AUTOSAR XML (schema 4-0-3)
package /CalibrationComponents
  parameter sw component type HVIR: data-type-mapping=HVIR_CodeDataTypeMappingsSet
    provide port HVIR_Pport: provided-interface=HVIR_if
      provided-com-specs:
        init-value=0.009999999776482582, parameter=KeHVIR_I_FastChgCurrentLoop
        init-value=0.009999999776482582, parameter=KeHVIR_I_MainCurrentLoop
        init-value=400, parameter=KeHVIR_R_FastChgLoopResThreshold
        init-value=400, parameter=KeHVIR_R_MainLoopResThreshold
        init-value=0, parameter=KeHVIR_U_HS_HVILFaultedDflt
        init-value=0, parameter=KeHVIR_U_HS_HVILFaultedDflt1
        init-value=0, parameter=KeHVIR_U_LS_HVILFaultedDflt
        init-value=0, parameter=KeHVIR_U_LS_HVILFaultedDflt1
        init-value=0, parameter=KeHVIR_U_OvrdHS2_HVILVal
        init-value=0, parameter=KeHVIR_U_OvrdHS_HVIL1Val
        init-value=0, parameter=KeHVIR_U_OvrdHS_HVILVal
        init-value=0, parameter=KeHVIR_U_OvrdLS2_HVILVal
        init-value=0, parameter=KeHVIR_U_OvrdLS_HVIL1Val
        init-value=0, parameter=KeHVIR_U_OvrdLS_HVILVal
        init-value=0.10000000149011612, parameter=KeHVIR_t_MainLoopHVILFltOffDbnc
        init-value=1, parameter=KeHVIR_t_MainLoopHVILFltOnDbnc
        init-value=0.009999999776482582, parameter=KeHVIR_t_SampleRate
        init-value=5, parameter=KeHVIR_Cnt_DbncFastChgCommFlt
        init-value=5, parameter=KeHVIR_Cnt_DbncMainCommFlt
        init-value=100, parameter=KeHVIR_Cnt_FastChgLoopHVILFltDbnc
        init-value=CeHVIR_e_HVIL_Closed, parameter=KeHVIR_e_MainHVIL2_StOvrdVal
        init-value=CeHVIR_e_HVIL_Closed, parameter=KeHVIR_e_MainHVIL_StOvrdVal
        init-value=CeHVIR_e_HVIL_ClosedFS, parameter=KeHVIR_e_FastChrgHVIL_StOvrdVal
        init-value=0, parameter=KeHVIR_b_FastChgHVIL_fltOvrd
        init-value=0, parameter=KeHVIR_b_FastChgHVIL_fltOvrdVal
        init-value=0, parameter=KeHVIR_b_FastChrgHVIL_StOvrdCtrl
        init-value=0, parameter=KeHVIR_b_MainHVIL2_StOvrd
        init-value=0, parameter=KeHVIR_b_MainHVIL2_flt_Ctrl
        init-value=0, parameter=KeHVIR_b_MainHVIL_StOvrd
        init-value=0, parameter=KeHVIR_b_MainHVIL_flt_Ctrl
        init-value=0, parameter=KeHVIR_b_OvrdHS2_HVILFltOvrd
        init-value=0, parameter=KeHVIR_b_OvrdHS2_HVILFltVal
        init-value=0, parameter=KeHVIR_b_OvrdHS2_HVILOvrd
        init-value=0, parameter=KeHVIR_b_OvrdHS_HVIL1Ovrd
        init-value=0, parameter=KeHVIR_b_OvrdHS_HVILFlt1Ovrd
        init-value=0, parameter=KeHVIR_b_OvrdHS_HVILFlt1Val
        init-value=0, parameter=KeHVIR_b_OvrdHS_HVILFltOvrd
        init-value=0, parameter=KeHVIR_b_OvrdHS_HVILFltVal
        init-value=0, parameter=KeHVIR_b_OvrdHS_HVILOvrd
        init-value=0, parameter=KeHVIR_b_OvrdLS2_HVILFltOvrd
        init-value=0, parameter=KeHVIR_b_OvrdLS2_HVILFltVal
        init-value=0, parameter=KeHVIR_b_OvrdLS2_HVILOvrd
        init-value=0, parameter=KeHVIR_b_OvrdLS_HVIL1Ovrd
        init-value=0, parameter=KeHVIR_b_OvrdLS_HVILFlt1Ovrd
        init-value=0, parameter=KeHVIR_b_OvrdLS_HVILFlt1Val
        init-value=0, parameter=KeHVIR_b_OvrdLS_HVILFltOvrd
        init-value=0, parameter=KeHVIR_b_OvrdLS_HVILFltVal
        init-value=0, parameter=KeHVIR_b_OvrdLS_HVILOvrd
        init-value=0, parameter=KeHVIR_k_MainHVIL2_flt_Val
        init-value=0, parameter=KeHVIR_k_MainHVIL_flt_Val
package /HVIR_Code_pkg/HVIR_Code_swc
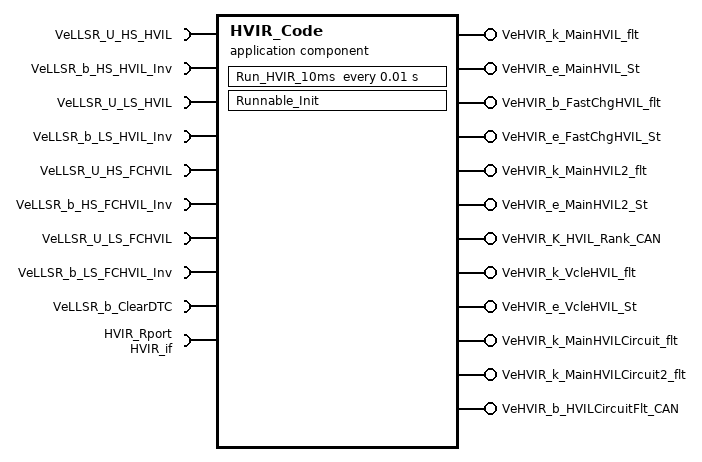
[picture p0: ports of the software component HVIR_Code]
  application sw component type HVIR_Code
    9 x require port:
      VeLLSR_U_HS_HVIL: nonqueued-receiver-com-spec{data-element=VeLLSR_U_HS_HVIL, init-value=0}, required-interface=VeLLSR_U_HS_HVIL
      VeLLSR_b_HS_HVIL_Inv: nonqueued-receiver-com-spec{data-element=VeLLSR_b_HS_HVIL_Inv, init-value=0}, required-interface=VeLLSR_b_HS_HVIL_Inv
      VeLLSR_U_LS_HVIL: nonqueued-receiver-com-spec{data-element=VeLLSR_U_LS_HVIL, init-value=0}, required-interface=VeLLSR_U_LS_HVIL
      VeLLSR_b_LS_HVIL_Inv: nonqueued-receiver-com-spec{data-element=VeLLSR_b_LS_HVIL_Inv, init-value=0}, required-interface=VeLLSR_b_LS_HVIL_Inv
      VeLLSR_U_HS_FCHVIL: nonqueued-receiver-com-spec{data-element=VeLLSR_U_HS_FCHVIL, init-value=0}, required-interface=VeLLSR_U_HS_FCHVIL
      VeLLSR_b_HS_FCHVIL_Inv: nonqueued-receiver-com-spec{data-element=VeLLSR_b_HS_FCHVIL_Inv, init-value=0}, required-interface=VeLLSR_b_HS_FCHVIL_Inv
      VeLLSR_U_LS_FCHVIL: nonqueued-receiver-com-spec{data-element=VeLLSR_U_LS_FCHVIL, init-value=0}, required-interface=VeLLSR_U_LS_FCHVIL
      VeLLSR_b_LS_FCHVIL_Inv: nonqueued-receiver-com-spec{data-element=VeLLSR_b_LS_FCHVIL_Inv, init-value=0}, required-interface=VeLLSR_b_LS_FCHVIL_Inv
      VeLLSR_b_ClearDTC: nonqueued-receiver-com-spec{data-element=VeLLSR_b_ClearDTC, init-value=0}, required-interface=VeLLSR_b_ClearDTC
    12 x provide port:
      VeHVIR_k_MainHVIL_flt: nonqueued-sender-com-spec{data-element=VeHVIR_k_MainHVIL_flt, init-value=0}, provided-interface=VeHVIR_k_MainHVIL_flt
      VeHVIR_e_MainHVIL_St: nonqueued-sender-com-spec{data-element=VeHVIR_e_MainHVIL_St, init-value=CeHVIR_e_HVIL_Closed}, provided-interface=VeHVIR_e_MainHVIL_St
      VeHVIR_b_FastChgHVIL_flt: nonqueued-sender-com-spec{data-element=VeHVIR_b_FastChgHVIL_flt, init-value=0}, provided-interface=VeHVIR_b_FastChgHVIL_flt
      VeHVIR_e_FastChgHVIL_St: nonqueued-sender-com-spec{data-element=VeHVIR_e_FastChgHVIL_St, init-value=CeHVIR_e_HVIL_ClosedFS}, provided-interface=VeHVIR_e_FastChgHVIL_St
      VeHVIR_k_MainHVIL2_flt: nonqueued-sender-com-spec{data-element=VeHVIR_k_MainHVIL2_flt, init-value=0}, provided-interface=VeHVIR_k_MainHVIL2_flt
      VeHVIR_e_MainHVIL2_St: nonqueued-sender-com-spec{data-element=VeHVIR_e_MainHVIL2_St, init-value=CeHVIR_e_HVIL_Closed}, provided-interface=VeHVIR_e_MainHVIL2_St
      VeHVIR_K_HVIL_Rank_CAN: nonqueued-sender-com-spec{data-element=VeHVIR_K_HVIL_Rank_CAN, init-value=0}, provided-interface=VeHVIR_K_HVIL_Rank_CAN
      VeHVIR_k_VcleHVIL_flt: nonqueued-sender-com-spec{data-element=VeHVIR_k_VcleHVIL_flt, init-value=0}, provided-interface=VeHVIR_k_VcleHVIL_flt
      VeHVIR_e_VcleHVIL_St: nonqueued-sender-com-spec{data-element=VeHVIR_e_VcleHVIL_St, init-value=0}, provided-interface=VeHVIR_e_VcleHVIL_St
      VeHVIR_k_MainHVILCircuit_flt: nonqueued-sender-com-spec{data-element=VeHVIR_k_MainHVILCircuit_flt, init-value=0}, provided-interface=VeHVIR_k_MainHVILCircuit_flt
      VeHVIR_k_MainHVILCircuit2_flt: nonqueued-sender-com-spec{data-element=VeHVIR_k_MainHVILCircuit2_flt, init-value=0}, provided-interface=VeHVIR_k_MainHVILCircuit2_flt
      VeHVIR_b_HVILCircuitFlt_CAN: nonqueued-sender-com-spec{data-element=VeHVIR_b_HVILCircuitFlt_CAN, init-value=0}, provided-interface=VeHVIR_b_HVILCircuitFlt_CAN
    require port HVIR_Rport: required-interface=HVIR_if
    behavior HVIR_Code: data-type-mapping=HVIR_CodeDataTypeMappingsSet, handle-termination-and-restart=NO-SUPPORT
      timing event Event_Run_HVIR_10ms: start-on-event=Run_HVIR_10ms, period=0.01
      runnable Runnable_Init: symbol=HVIR_Code_Init
      runnable Run_HVIR_10ms
        data-read-access:
          9 x access:
            IN_VeLLSR_U_HS_FCHVIL_VeLLSR_U_HS_FCHVIL: accessed-variable=VeLLSR_U_HS_FCHVIL.VeLLSR_U_HS_FCHVIL
            IN_VeLLSR_U_HS_HVIL_VeLLSR_U_HS_HVIL: accessed-variable=VeLLSR_U_HS_HVIL.VeLLSR_U_HS_HVIL
            IN_VeLLSR_U_LS_FCHVIL_VeLLSR_U_LS_FCHVIL: accessed-variable=VeLLSR_U_LS_FCHVIL.VeLLSR_U_LS_FCHVIL
            IN_VeLLSR_U_LS_HVIL_VeLLSR_U_LS_HVIL: accessed-variable=VeLLSR_U_LS_HVIL.VeLLSR_U_LS_HVIL
            IN_VeLLSR_b_ClearDTC_VeLLSR_b_ClearDTC: accessed-variable=VeLLSR_b_ClearDTC.VeLLSR_b_ClearDTC
            IN_VeLLSR_b_HS_FCHVIL_Inv_VeLLSR_b_HS_FCHVIL_Inv: accessed-variable=VeLLSR_b_HS_FCHVIL_Inv.VeLLSR_b_HS_FCHVIL_Inv
            IN_VeLLSR_b_HS_HVIL_Inv_VeLLSR_b_HS_HVIL_Inv: accessed-variable=VeLLSR_b_HS_HVIL_Inv.VeLLSR_b_HS_HVIL_Inv
            IN_VeLLSR_b_LS_FCHVIL_Inv_VeLLSR_b_LS_FCHVIL_Inv: accessed-variable=VeLLSR_b_LS_FCHVIL_Inv.VeLLSR_b_LS_FCHVIL_Inv
            IN_VeLLSR_b_LS_HVIL_Inv_VeLLSR_b_LS_HVIL_Inv: accessed-variable=VeLLSR_b_LS_HVIL_Inv.VeLLSR_b_LS_HVIL_Inv
        data-send-points:
          12 x access:
            OUT_VeHVIR_k_MainHVIL_flt_VeHVIR_k_MainHVIL_flt: accessed-variable=VeHVIR_k_MainHVIL_flt.VeHVIR_k_MainHVIL_flt
            OUT_VeHVIR_e_MainHVIL_St_VeHVIR_e_MainHVIL_St: accessed-variable=VeHVIR_e_MainHVIL_St.VeHVIR_e_MainHVIL_St
            OUT_VeHVIR_b_FastChgHVIL_flt_VeHVIR_b_FastChgHVIL_flt: accessed-variable=VeHVIR_b_FastChgHVIL_flt.VeHVIR_b_FastChgHVIL_flt
            OUT_VeHVIR_e_FastChgHVIL_St_VeHVIR_e_FastChgHVIL_St: accessed-variable=VeHVIR_e_FastChgHVIL_St.VeHVIR_e_FastChgHVIL_St
            OUT_VeHVIR_k_MainHVIL2_flt_VeHVIR_k_MainHVIL2_flt: accessed-variable=VeHVIR_k_MainHVIL2_flt.VeHVIR_k_MainHVIL2_flt
            OUT_VeHVIR_e_MainHVIL2_St_VeHVIR_e_MainHVIL2_St: accessed-variable=VeHVIR_e_MainHVIL2_St.VeHVIR_e_MainHVIL2_St
            OUT_VeHVIR_K_HVIL_Rank_CAN_VeHVIR_K_HVIL_Rank_CAN: accessed-variable=VeHVIR_K_HVIL_Rank_CAN.VeHVIR_K_HVIL_Rank_CAN
            OUT_VeHVIR_k_VcleHVIL_flt_VeHVIR_k_VcleHVIL_flt: accessed-variable=VeHVIR_k_VcleHVIL_flt.VeHVIR_k_VcleHVIL_flt
            OUT_VeHVIR_e_VcleHVIL_St_VeHVIR_e_VcleHVIL_St: accessed-variable=VeHVIR_e_VcleHVIL_St.VeHVIR_e_VcleHVIL_St
            OUT_VeHVIR_k_MainHVILCircuit_flt_VeHVIR_k_MainHVILCircuit_flt: accessed-variable=VeHVIR_k_MainHVILCircuit_flt.VeHVIR_k_MainHVILCircuit_flt
            OUT_VeHVIR_k_MainHVILCircuit2_flt_VeHVIR_k_Ma_b7ce7321b4a68780: accessed-variable=VeHVIR_k_MainHVILCircuit2_flt.VeHVIR_k_MainHVILCircuit2_flt
            OUT_VeHVIR_b_HVILCircuitFlt_CAN_VeHVIR_b_HVILCircuitFlt_CAN: accessed-variable=VeHVIR_b_HVILCircuitFlt_CAN.VeHVIR_b_HVILCircuitFlt_CAN
        50 x parameter access:
          CALPRM_HVIR_Rport_KeHVIR_Cnt_DbncFastChgCommFlt: accessed-parameter=HVIR_Rport.KeHVIR_Cnt_DbncFastChgCommFlt
          CALPRM_HVIR_Rport_KeHVIR_Cnt_DbncMainCommFlt: accessed-parameter=HVIR_Rport.KeHVIR_Cnt_DbncMainCommFlt
          CALPRM_HVIR_Rport_KeHVIR_Cnt_FastChgLoopHVILFltDbnc: accessed-parameter=HVIR_Rport.KeHVIR_Cnt_FastChgLoopHVILFltDbnc
          CALPRM_HVIR_Rport_KeHVIR_I_FastChgCurrentLoop: accessed-parameter=HVIR_Rport.KeHVIR_I_FastChgCurrentLoop
          CALPRM_HVIR_Rport_KeHVIR_I_MainCurrentLoop: accessed-parameter=HVIR_Rport.KeHVIR_I_MainCurrentLoop
          CALPRM_HVIR_Rport_KeHVIR_R_FastChgLoopResThreshold: accessed-parameter=HVIR_Rport.KeHVIR_R_FastChgLoopResThreshold
          CALPRM_HVIR_Rport_KeHVIR_R_MainLoopResThreshold: accessed-parameter=HVIR_Rport.KeHVIR_R_MainLoopResThreshold
          CALPRM_HVIR_Rport_KeHVIR_U_HS_HVILFaultedDflt: accessed-parameter=HVIR_Rport.KeHVIR_U_HS_HVILFaultedDflt
          CALPRM_HVIR_Rport_KeHVIR_U_HS_HVILFaultedDflt1: accessed-parameter=HVIR_Rport.KeHVIR_U_HS_HVILFaultedDflt1
          CALPRM_HVIR_Rport_KeHVIR_U_LS_HVILFaultedDflt: accessed-parameter=HVIR_Rport.KeHVIR_U_LS_HVILFaultedDflt
          CALPRM_HVIR_Rport_KeHVIR_U_LS_HVILFaultedDflt1: accessed-parameter=HVIR_Rport.KeHVIR_U_LS_HVILFaultedDflt1
          CALPRM_HVIR_Rport_KeHVIR_U_OvrdHS2_HVILVal: accessed-parameter=HVIR_Rport.KeHVIR_U_OvrdHS2_HVILVal
          CALPRM_HVIR_Rport_KeHVIR_U_OvrdHS_HVIL1Val: accessed-parameter=HVIR_Rport.KeHVIR_U_OvrdHS_HVIL1Val
          CALPRM_HVIR_Rport_KeHVIR_U_OvrdHS_HVILVal: accessed-parameter=HVIR_Rport.KeHVIR_U_OvrdHS_HVILVal
          CALPRM_HVIR_Rport_KeHVIR_U_OvrdLS2_HVILVal: accessed-parameter=HVIR_Rport.KeHVIR_U_OvrdLS2_HVILVal
          CALPRM_HVIR_Rport_KeHVIR_U_OvrdLS_HVIL1Val: accessed-parameter=HVIR_Rport.KeHVIR_U_OvrdLS_HVIL1Val
          CALPRM_HVIR_Rport_KeHVIR_U_OvrdLS_HVILVal: accessed-parameter=HVIR_Rport.KeHVIR_U_OvrdLS_HVILVal
          CALPRM_HVIR_Rport_KeHVIR_b_FastChgHVIL_fltOvrd: accessed-parameter=HVIR_Rport.KeHVIR_b_FastChgHVIL_fltOvrd
          CALPRM_HVIR_Rport_KeHVIR_b_FastChgHVIL_fltOvrdVal: accessed-parameter=HVIR_Rport.KeHVIR_b_FastChgHVIL_fltOvrdVal
          CALPRM_HVIR_Rport_KeHVIR_b_FastChrgHVIL_StOvrdCtrl: accessed-parameter=HVIR_Rport.KeHVIR_b_FastChrgHVIL_StOvrdCtrl
          CALPRM_HVIR_Rport_KeHVIR_b_MainHVIL2_StOvrd: accessed-parameter=HVIR_Rport.KeHVIR_b_MainHVIL2_StOvrd
          CALPRM_HVIR_Rport_KeHVIR_b_MainHVIL2_flt_Ctrl: accessed-parameter=HVIR_Rport.KeHVIR_b_MainHVIL2_flt_Ctrl
          CALPRM_HVIR_Rport_KeHVIR_b_MainHVIL_StOvrd: accessed-parameter=HVIR_Rport.KeHVIR_b_MainHVIL_StOvrd
          CALPRM_HVIR_Rport_KeHVIR_b_MainHVIL_flt_Ctrl: accessed-parameter=HVIR_Rport.KeHVIR_b_MainHVIL_flt_Ctrl
          CALPRM_HVIR_Rport_KeHVIR_b_OvrdHS2_HVILFltOvrd: accessed-parameter=HVIR_Rport.KeHVIR_b_OvrdHS2_HVILFltOvrd
          CALPRM_HVIR_Rport_KeHVIR_b_OvrdHS2_HVILFltVal: accessed-parameter=HVIR_Rport.KeHVIR_b_OvrdHS2_HVILFltVal
          CALPRM_HVIR_Rport_KeHVIR_b_OvrdHS2_HVILOvrd: accessed-parameter=HVIR_Rport.KeHVIR_b_OvrdHS2_HVILOvrd
          CALPRM_HVIR_Rport_KeHVIR_b_OvrdHS_HVIL1Ovrd: accessed-parameter=HVIR_Rport.KeHVIR_b_OvrdHS_HVIL1Ovrd
          CALPRM_HVIR_Rport_KeHVIR_b_OvrdHS_HVILFlt1Ovrd: accessed-parameter=HVIR_Rport.KeHVIR_b_OvrdHS_HVILFlt1Ovrd
          CALPRM_HVIR_Rport_KeHVIR_b_OvrdHS_HVILFlt1Val: accessed-parameter=HVIR_Rport.KeHVIR_b_OvrdHS_HVILFlt1Val
          CALPRM_HVIR_Rport_KeHVIR_b_OvrdHS_HVILFltOvrd: accessed-parameter=HVIR_Rport.KeHVIR_b_OvrdHS_HVILFltOvrd
          CALPRM_HVIR_Rport_KeHVIR_b_OvrdHS_HVILFltVal: accessed-parameter=HVIR_Rport.KeHVIR_b_OvrdHS_HVILFltVal
          CALPRM_HVIR_Rport_KeHVIR_b_OvrdHS_HVILOvrd: accessed-parameter=HVIR_Rport.KeHVIR_b_OvrdHS_HVILOvrd
          CALPRM_HVIR_Rport_KeHVIR_b_OvrdLS2_HVILFltOvrd: accessed-parameter=HVIR_Rport.KeHVIR_b_OvrdLS2_HVILFltOvrd
          CALPRM_HVIR_Rport_KeHVIR_b_OvrdLS2_HVILFltVal: accessed-parameter=HVIR_Rport.KeHVIR_b_OvrdLS2_HVILFltVal
          CALPRM_HVIR_Rport_KeHVIR_b_OvrdLS2_HVILOvrd: accessed-parameter=HVIR_Rport.KeHVIR_b_OvrdLS2_HVILOvrd
          CALPRM_HVIR_Rport_KeHVIR_b_OvrdLS_HVIL1Ovrd: accessed-parameter=HVIR_Rport.KeHVIR_b_OvrdLS_HVIL1Ovrd
          CALPRM_HVIR_Rport_KeHVIR_b_OvrdLS_HVILFlt1Ovrd: accessed-parameter=HVIR_Rport.KeHVIR_b_OvrdLS_HVILFlt1Ovrd
          CALPRM_HVIR_Rport_KeHVIR_b_OvrdLS_HVILFlt1Val: accessed-parameter=HVIR_Rport.KeHVIR_b_OvrdLS_HVILFlt1Val
          CALPRM_HVIR_Rport_KeHVIR_b_OvrdLS_HVILFltOvrd: accessed-parameter=HVIR_Rport.KeHVIR_b_OvrdLS_HVILFltOvrd
          CALPRM_HVIR_Rport_KeHVIR_b_OvrdLS_HVILFltVal: accessed-parameter=HVIR_Rport.KeHVIR_b_OvrdLS_HVILFltVal
          CALPRM_HVIR_Rport_KeHVIR_b_OvrdLS_HVILOvrd: accessed-parameter=HVIR_Rport.KeHVIR_b_OvrdLS_HVILOvrd
          CALPRM_HVIR_Rport_KeHVIR_e_FastChrgHVIL_StOvrdVal: accessed-parameter=HVIR_Rport.KeHVIR_e_FastChrgHVIL_StOvrdVal
          CALPRM_HVIR_Rport_KeHVIR_e_MainHVIL2_StOvrdVal: accessed-parameter=HVIR_Rport.KeHVIR_e_MainHVIL2_StOvrdVal
          CALPRM_HVIR_Rport_KeHVIR_e_MainHVIL_StOvrdVal: accessed-parameter=HVIR_Rport.KeHVIR_e_MainHVIL_StOvrdVal
          CALPRM_HVIR_Rport_KeHVIR_k_MainHVIL2_flt_Val: accessed-parameter=HVIR_Rport.KeHVIR_k_MainHVIL2_flt_Val
          CALPRM_HVIR_Rport_KeHVIR_k_MainHVIL_flt_Val: accessed-parameter=HVIR_Rport.KeHVIR_k_MainHVIL_flt_Val
          CALPRM_HVIR_Rport_KeHVIR_t_MainLoopHVILFltOffDbnc: accessed-parameter=HVIR_Rport.KeHVIR_t_MainLoopHVILFltOffDbnc
          CALPRM_HVIR_Rport_KeHVIR_t_MainLoopHVILFltOnDbnc: accessed-parameter=HVIR_Rport.KeHVIR_t_MainLoopHVILFltOnDbnc
          CALPRM_HVIR_Rport_KeHVIR_t_SampleRate: accessed-parameter=HVIR_Rport.KeHVIR_t_SampleRate
